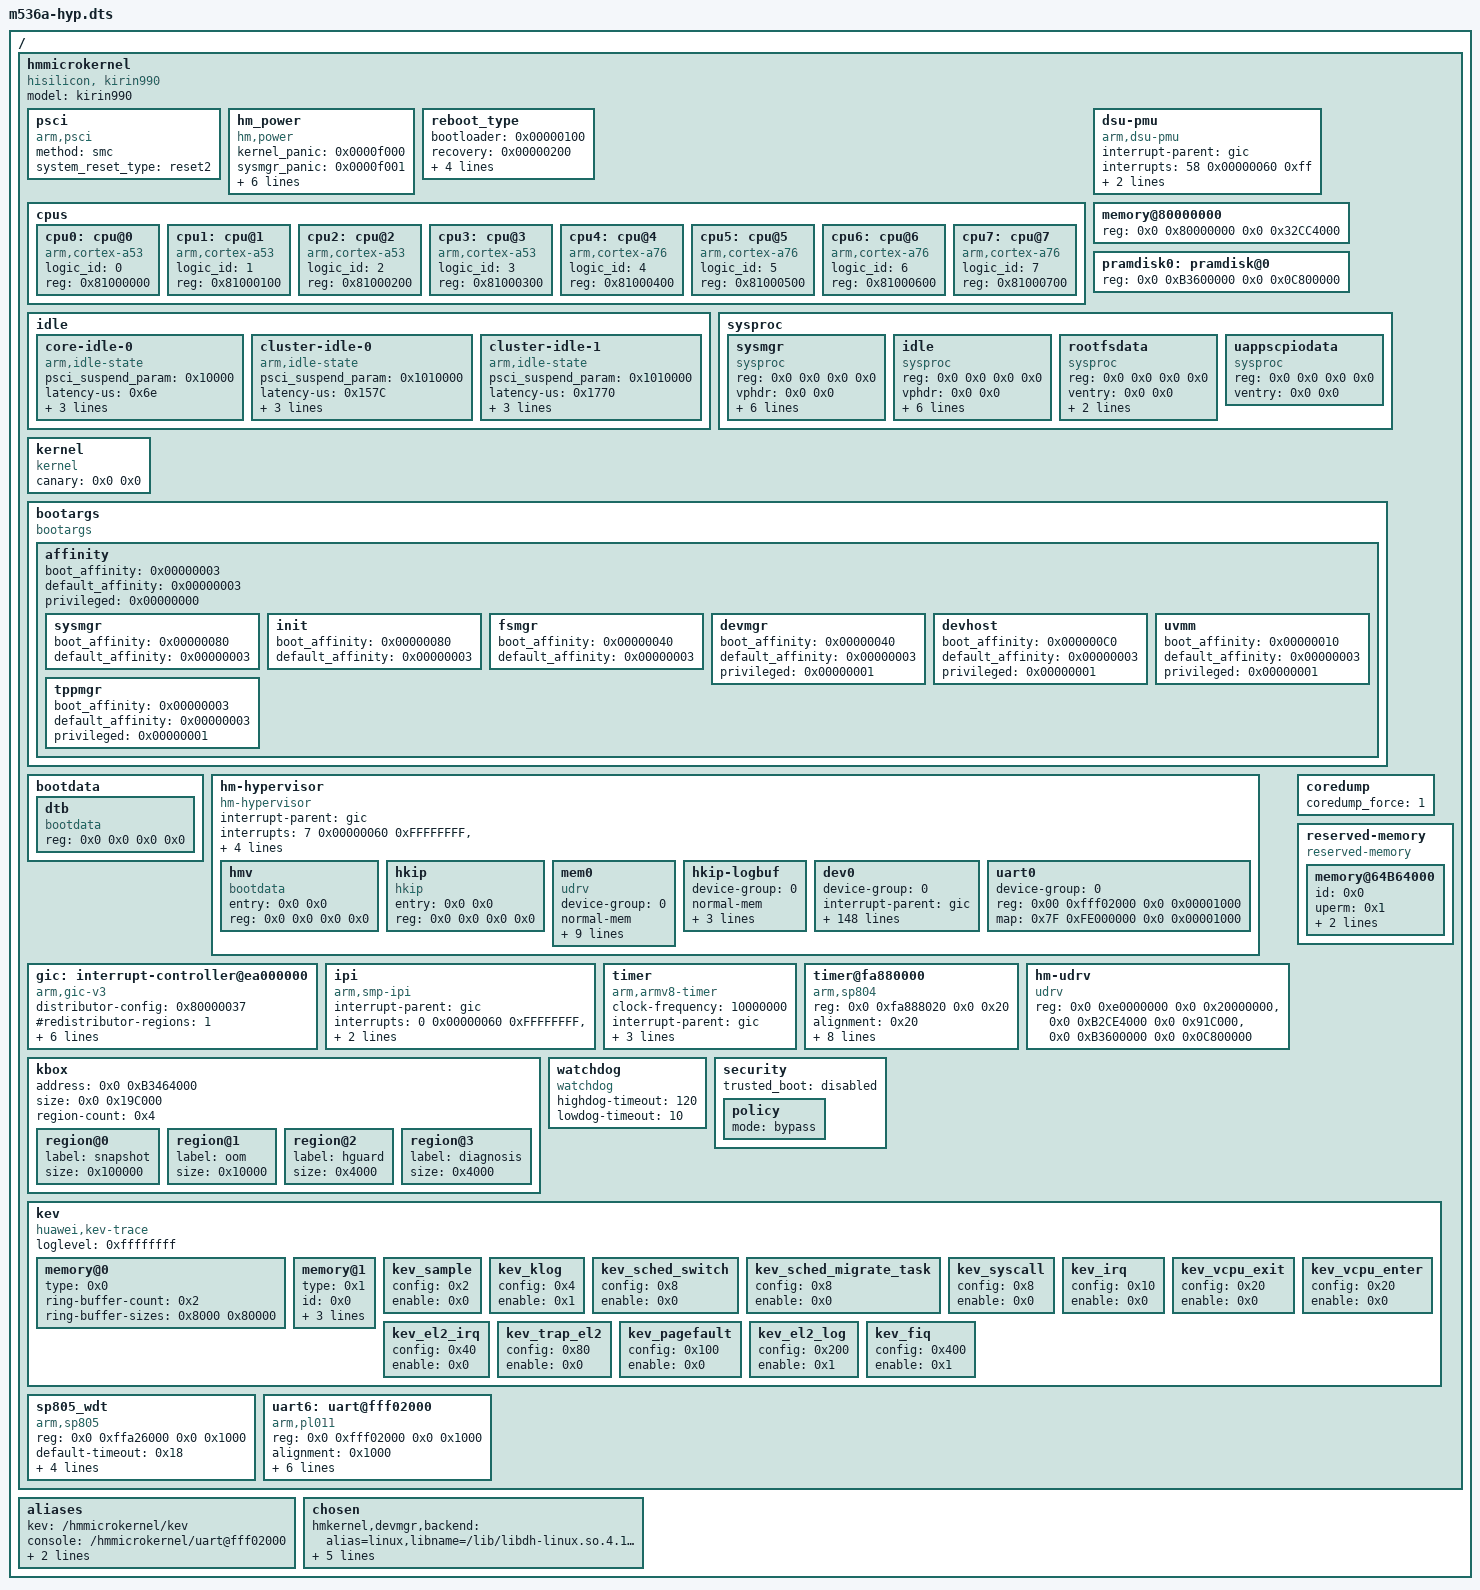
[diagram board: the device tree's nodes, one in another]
/dts-v1/;
/ { #address-cells = <2>; #size-cells = <2>; hmmicrokernel {
	model = "kirin990";
	compatible = "hisilicon, kirin990";
	#address-cells = <2>;
	#size-cells = <2>;

	psci {
		compatible = "arm,psci";
		method = "smc";
		system_reset_type = "reset2";
	};

	hm_power {
		compatible = "hm,power";
		kernel_panic = <0x0000f000>;
		sysmgr_panic = <0x0000f001>;
		init_panic = <0x0000f002>;
		harddog_hungry = <0x0000f003>;
		lowdog_hungry = <0x0000f004>;
		highdog_hungry = <0x0000f005>;
		coldboot = <0x00001000>;
		suspend_state = <0x01010000>;
	};

	reboot_type {
		bootloader = <0x00000100>;
		recovery = <0x00000200>;
		no_reason = <0x0000ff00>;
		vwatchdog = <0x0000f080>;
		fastboot = <0x00002e00>;
		hguard_service = <0x0000f081>;
	};

	cpus {
		#address-cells = <1>;
		#size-cells = <0>;
		cpu0: cpu@0 {
			compatible = "arm,cortex-a53", "arm,armv8";
			device_type = "cpu";
			logic_id = <0>;
			reg = <0x81000000>;
		};
		cpu1: cpu@1 {
			compatible = "arm,cortex-a53", "arm,armv8";
			device_type = "cpu";
			logic_id = <1>;
			reg = <0x81000100>;
		};
		cpu2: cpu@2 {
			compatible = "arm,cortex-a53", "arm,armv8";
			device_type = "cpu";
			logic_id = <2>;
			reg = <0x81000200>;
		};
		cpu3: cpu@3 {
			compatible = "arm,cortex-a53", "arm,armv8";
			device_type = "cpu";
			logic_id = <3>;
			reg = <0x81000300>;
		};
		cpu4: cpu@4 {
			compatible = "arm,cortex-a76", "arm,armv8";
			device_type = "cpu";
			logic_id = <4>;
			reg = <0x81000400>;
		};
		cpu5: cpu@5 {
			compatible = "arm,cortex-a76", "arm,armv8";
			device_type = "cpu";
			logic_id = <5>;
			reg = <0x81000500>;
		};
		cpu6: cpu@6 {
			compatible = "arm,cortex-a76", "arm,armv8";
			device_type = "cpu";
			logic_id = <6>;
			reg = <0x81000600>;
		};
		cpu7: cpu@7 {
			compatible = "arm,cortex-a76", "arm,armv8";
			device_type = "cpu";
			logic_id = <7>;
			reg = <0x81000700>;
		};
	};

	idle {
		core-idle-0 {
			compatible = "arm,idle-state";
			psci_suspend_param = <0x10000>;
			latency-us = <0x6e>;
			min-idletime-us = <0xbb8>;
			timer-stop;
			cpus = <0xff>;
		};
		cluster-idle-0 {
			compatible = "arm,idle-state";
			psci_suspend_param = <0x1010000>;
			latency-us = <0x157C>;
			min-idletime-us = <0x4e20>;
			timer-stop;
			cpus = <0xf>;
		};
		cluster-idle-1 {
			compatible = "arm,idle-state";
			psci_suspend_param = <0x1010000>;
			latency-us = <0x1770>;
			min-idletime-us = <0x3a98>;
			timer-stop;
			cpus = <0xf0>;
		};
	};

	dsu-pmu {
		compatible = "arm,dsu-pmu";
		interrupt-parent = <&gic>;
		interrupts = <58 0x00000060 0xff>;
		cpus = <&cpu0>, <&cpu1>, <&cpu2>, <&cpu3>,
			<&cpu4>, <&cpu5>, <&cpu6>, <&cpu7>;
	};

	memory@80000000 {
		device_type = "memory";
		reg = <0x0 0x80000000 0x0 0x32CC4000>;
	};

	/*
	 * used for kernel to map ramdisk memory as normal memory.
	 * memory range in this node should be exactly the same as the one in overlay-hyp.dts
	 */
	pramdisk0: pramdisk@0 {
		reg = <0x0 0xB3600000 0x0 0x0C800000>;
	};

	sysproc {
		#address-cells = <2>;
		#size-cells = <2>;
		sysmgr {
			compatible = "sysproc", "sysmgr";
			/* filled by bootloader */
			reg      = <0x0 0x0 0x0 0x0>;
			vphdr    = <0x0 0x0>;
			ventry   = <0x0 0x0>;
			pvoffset = <0x0 0x0>;
			nphdrs   = <0>;
			stack_start = <0x0 0x0>;
			stack_end = <0x0 0x0>;
			canary = <0x0 0x0>;
		};
		idle {
			compatible = "sysproc", "idle";
			/* filled by bootloader */
			reg      = <0x0 0x0 0x0 0x0>;
			vphdr    = <0x0 0x0>;
			ventry   = <0x0 0x0>;
			pvoffset = <0x0 0x0>;
			nphdrs   = <0>;
			stack_start = <0x0 0x0>;
			stack_end = <0x0 0x0>;
			canary = <0x0 0x0>;
		};
		rootfsdata {
			compatible = "sysproc", "rootfs";
			/* filled by bootloader */
			reg      = <0x0 0x0 0x0 0x0>;
			ventry   = <0x0 0x0>;
			pvoffset = <0x0 0x0>;
			jump_back = <0x0 0x0>;
		};

		uappscpiodata {
			compatible = "sysproc", "uappscpio";
			/* filled by bootloader */
			reg      = <0x0 0x0 0x0 0x0>;
			ventry   = <0x0 0x0>;
		};
	};

	kernel {
		compatible = "kernel";
		/* filled by bootloader */
		canary = <0x0 0x0>;
	};

	bootargs {
		compatible = "bootargs";
		affinity {
			boot_affinity = <0x00000003>;			/* 2 little cores */
			default_affinity = <0x00000003>;		/* 2 little cores */
			privileged = <0x00000000>;
			sysmgr {
				boot_affinity = <0x00000080>;		/* 1 big core */
				default_affinity = <0x00000003>;	/* 2 little cores */
			};
			init {
				boot_affinity = <0x00000080>;		/* 1 big core */
				default_affinity = <0x00000003>;	/* 2 little cores */
			};
			fsmgr {
				boot_affinity = <0x00000040>;		/* 1 big core */
				default_affinity = <0x00000003>;	/* 2 little cores */
			};
			devmgr {
				boot_affinity = <0x00000040>;		/* 1 big core */
				default_affinity = <0x00000003>;	/* 2 little cores */
				privileged = <0x00000001>;
			};
			devhost {
				boot_affinity = <0x000000C0>;		/* 2 big cores */
				default_affinity = <0x00000003>;	/* 2 little cores */
				privileged = <0x00000001>;
			};
			uvmm {
				boot_affinity = <0x00000010>;		/* 1 middle core */
				default_affinity = <0x00000003>;	/* 2 little cores */
				privileged = <0x00000001>;
			};
			tppmgr {
				boot_affinity = <0x00000003>;		/* 2 little cores */
				default_affinity = <0x00000003>;	/* 2 little cores */
				privileged = <0x00000001>;
			};
		};
	};

	bootdata {
		#address-cells = <2>;
		#size-cells = <2>;
		dtb {
			compatible = "bootdata", "dtb";
			/* filled by bootloader */
			reg = <0x0 0x0 0x0 0x0>;
		};
	};

	hm-hypervisor {
		compatible = "hm-hypervisor";
		#address-cells = <2>;
		#size-cells = <2>;

		interrupt-parent = <&gic>;
		interrupts = <7 0x00000060 0xFFFFFFFF>,
			     <25 0x00000060 0xFFFFFFFF>,
			     <27 0x00000060 0xFFFFFFFF>;

		virtual-timer-irq = <27>;
		vgic-base-address = <0x7F 0xFF000000>;

		hmv {
			compatible = "bootdata";
			/* filled by bootloader */
			entry = <0x0 0x0>;
			reg = <0x0 0x0 0x0 0x0>;
		};

		hkip {
			compatible = "hkip";
			/* filled by bootloader */
			entry = <0x0 0x0>;
			reg = <0x0 0x0 0x0 0x0>;
		};

		/* for vm0*/
		mem0 {
			device-group = <0>;
			compatible = "udrv";
			normal-mem;
			uvmm-access;
			reg = <0x0 0x00000000 0x0 0x80000000>,
			      <0x0 0xC0000000 0x0 0x20000000>,
			      <0x1 0x00000000 0x1 0x00000000>,
			      <0x8 0x00000000 0x0 0x20000000>;
			map = <0x0 0x00000000 0x0 0x80000000>,
			      <0x0 0xC0000000 0x0 0x20000000>,
			      <0x1 0x00000000 0x1 0x00000000>,
			      <0x8 0x00000000 0x0 0x20000000>;
		};

		hkip-logbuf {
			device-group = <0>;
			normal-mem;
			hkip-logbuf;
			reg = <0x0 0xB2CC4000 0x0 0x00020000>;
			map = <0x0 0xB2CC4000 0x0 0x00020000>;
		};

		dev0 {
			device-group = <0>;
			interrupt-parent = <&gic>;
			interrupts = <80 0x000000E0 0xFFFFFFFF>, /* timer */
				     <113 0x000000E0 0xFFFFFFFF>, /* i2c */
				     <114 0x000000E0 0xFFFFFFFF>, /* i2c */
				     <257 0x000000E0 0xFFFFFFFF>, /* i2c */
				     <346 0x000000E0 0xFFFFFFFF>, /* i2c */
				     <344 0x000000E0 0xFFFFFFFF>, /* pl022 */
				     <304 0x000000E0 0xFFFFFFFF>, /* isp */
				     <475 0x000000E0 0xFFFFFFFF>, /* HISP_CPE_IRQ */
				     <310 0x000000E0 0xFFFFFFFF>, /* ufs */
				     <169 0x000000E0 0xFFFFFFFF>, /* ufs-timer */
				     <224 0x000000E0 0xFFFFFFFF>, /* mailbox */
				     <225 0x000000E0 0xFFFFFFFF>, /* mailbox */
				     <229 0x000000E0 0xFFFFFFFF>, /* mailbox */
				     <230 0x000000E0 0xFFFFFFFF>, /* mailbox */
				     <231 0x000000E0 0xFFFFFFFF>, /* mailbox */
				     <232 0x000000E0 0xFFFFFFFF>, /* mailbox */
				     <233 0x000000E0 0xFFFFFFFF>, /* mailbox */
				     <234 0x000000E0 0xFFFFFFFF>, /* mailbox */
				     <235 0x000000E0 0xFFFFFFFF>, /* mailbox */
				     <237 0x000000E0 0xFFFFFFFF>, /* mailbox */
				     <238 0x000000E0 0xFFFFFFFF>, /* mailbox */
				     <205 0x000000E0 0xFFFFFFFF>, /* mailbox */
				     <204 0x000000E0 0xFFFFFFFF>, /* mailbox */
				     <470 0x020000E0 0xFFFFFFFF>, /* cmd-intr */
				     <472 0x020000E0 0xFFFFFFFF>, /* dfx-intr */
				     <32 0x000000E0 0xFFFFFFFF>, /* errirq */
				     <41 0x000000E0 0xFFFFFFFF>, /* faultirq */
				     <52 0x000000E0 0xFFFFFFFF>, /* pmu */
				     <53 0x000000E0 0xFFFFFFFF>, /* pmu */
				     <54 0x000000E0 0xFFFFFFFF>, /* pmu */
				     <55 0x000000E0 0xFFFFFFFF>, /* pmu */
				     <56 0x000000E0 0xFFFFFFFF>, /* pmu */
				     <57 0x000000E0 0xFFFFFFFF>, /* pmu */
				     <315 0x000000E0 0xFFFFFFFF>, /* kirin-pcie0-msi */
				     <316 0x020000E0 0xFFFFFFFF>, /* kirin-pcie0-intc */
				     <317 0x020000E0 0xFFFFFFFF>, /* kirin-pcie0-intd */
				     <313 0x020000E0 0xFFFFFFFF>, /* kirin-pcie0-linkdown */
				     <243 0x020000E0 0xFFFFFFFF>, /* kirin-pcie0-cpltimeout */
				     <449 0x000000E0 0xFFFFFFFF>, /* kirin-pcie1-msi */
				     <450 0x020000E0 0xFFFFFFFF>, /* kirin-pcie1-intc */
				     <451 0x020000E0 0xFFFFFFFF>, /* kirin-pcie1-intd */
				     <415 0x020000E0 0xFFFFFFFF>, /* kirin-pcie1-linkdown */
				     <244 0x020000E0 0xFFFFFFFF>, /* kirin-pcie1-cpltimeout */
				     <290 0x000000E0 0xFFFFFFFF>, /* gpu */
				     <291 0x000000E0 0xFFFFFFFF>, /* gpu */
				     <292 0x000000E0 0xFFFFFFFF>, /* gpu */
				     <277 0x000000E0 0xFFFFFFFF>, /* irq_pdp */
				     <278 0x000000E0 0xFFFFFFFF>, /* irq_pdp */
				     <279 0x000000E0 0xFFFFFFFF>, /* irq_adp */
				     <283 0x000000E0 0xFFFFFFFF>, /* irq_dsi0 */
				     <284 0x000000E0 0xFFFFFFFF>, /* irq_dsi0 */
				     <363 0x000000E0 0xFFFFFFFF>, /* dwc_dptx */
				     <319 0x000000E0 0xFFFFFFFF>, /* irq_mdc */
				     <388 0x000000E0 0xFFFFFFFF>, /* irq_sdp */
				     <335 0x000000E0 0xFFFFFFFF>, /* irq_jpu_dec_merged */
				     <175 0x000000E0 0xFFFFFFFF>, /* hisi-dma64 */
				     <376 0x000000E0 0xFFFFFFFF>, /* tc_ns_client */
				     <465 0x000000E0 0xFFFFFFFF>, /* npu-mailbox-0 */
				     <467 0x000000E0 0xFFFFFFFF>, /* npu-mailbox-4 */
				     <468 0x000000E0 0xFFFFFFFF>, /* npu-mailbox-5 */
				     <569 0x000000E0 0xFFFFFFFF>, /* hisi-mmu-v8-gerror */
				     <248 0x000000E0 0xFFFFFFFF>, /* asp_dma_irq */
				     <245 0x000000E0 0xFFFFFFFF>, /* soc wdt handler */
				     <191 0x000000E0 0xFFFFFFFF>, /* dwc3 */
				     <78 0x000000E0 0xFFFFFFFF>, /* hisi-soc-rtc */
				     <116 0x000000E0 0xFFFFFFFF>, /* gpio interrupt */
				     <117 0x000000E0 0xFFFFFFFF>, /* gpio interrupt */
				     <118 0x000000E0 0xFFFFFFFF>, /* gpio interrupt */
				     <119 0x000000E0 0xFFFFFFFF>, /* gpio interrupt */
				     <120 0x000000E0 0xFFFFFFFF>, /* gpio interrupt */
				     <121 0x000000E0 0xFFFFFFFF>, /* gpio interrupt */
				     <122 0x000000E0 0xFFFFFFFF>, /* gpio interrupt */
				     <123 0x000000E0 0xFFFFFFFF>, /* gpio interrupt */
				     <124 0x000000E0 0xFFFFFFFF>, /* gpio interrupt */
				     <125 0x000000E0 0xFFFFFFFF>, /* gpio interrupt */
				     <126 0x000000E0 0xFFFFFFFF>, /* gpio interrupt */
				     <127 0x000000E0 0xFFFFFFFF>, /* gpio interrupt */
				     <128 0x000000E0 0xFFFFFFFF>, /* gpio interrupt */
				     <129 0x000000E0 0xFFFFFFFF>, /* gpio interrupt */
				     <130 0x000000E0 0xFFFFFFFF>, /* gpio interrupt */
				     <131 0x000000E0 0xFFFFFFFF>, /* gpio interrupt */
				     <132 0x000000E0 0xFFFFFFFF>, /* gpio interrupt */
				     <133 0x000000E0 0xFFFFFFFF>, /* gpio interrupt */
				     <134 0x000000E0 0xFFFFFFFF>, /* gpio interrupt */
				     <135 0x000000E0 0xFFFFFFFF>, /* gpio interrupt */
				     <136 0x000000E0 0xFFFFFFFF>, /* gpio interrupt */
				     <137 0x000000E0 0xFFFFFFFF>, /* gpio interrupt */
				     <138 0x000000E0 0xFFFFFFFF>, /* gpio interrupt */
				     <139 0x000000E0 0xFFFFFFFF>, /* gpio interrupt */
				     <140 0x000000E0 0xFFFFFFFF>, /* gpio interrupt */
				     <141 0x000000E0 0xFFFFFFFF>, /* gpio interrupt */
				     <142 0x000000E0 0xFFFFFFFF>, /* gpio interrupt */
				     <143 0x000000E0 0xFFFFFFFF>, /* gpio interrupt */
				     <144 0x000000E0 0xFFFFFFFF>, /* gpio interrupt */
				     <145 0x000000E0 0xFFFFFFFF>, /* gpio interrupt */
				     <146 0x000000E0 0xFFFFFFFF>, /* gpio interrupt */
				     <147 0x000000E0 0xFFFFFFFF>, /* gpio interrupt */
				     <148 0x000000E0 0xFFFFFFFF>, /* gpio interrupt */
				     <149 0x000000E0 0xFFFFFFFF>, /* gpio interrupt */
				     <150 0x000000E0 0xFFFFFFFF>, /* gpio interrupt */
				     <151 0x000000E0 0xFFFFFFFF>, /* gpio interrupt */
				     <152 0x000000E0 0xFFFFFFFF>, /* gpio interrupt */
				     <168 0x000000E0 0xFFFFFFFF>, /* asp irq */
				     <409 0x000000E0 0xFFFFFFFF>, /* hisilicon,designware-i2c */
				     <410 0x000000E0 0xFFFFFFFF>, /* hisilicon,designware-i2c */
				     <404 0x000000E0 0xFFFFFFFF>, /* spi */
				     <112 0x000000E0 0xFFFFFFFF>, /* spi */
				     <167 0x000000E0 0xFFFFFFFF>, /* dx,cc63p */
				     <81 0x000000E0 0xFFFFFFFF>, /* timer */
				     <336 0x000000E0 0xFFFFFFFF>, /* hisp-hfd */
				     <176 0x000000E0 0xFFFFFFFF>, /* pimon_mntn */
				     <334 0x000000E0 0xFFFFFFFF>, /* hjpeg */
				     <91 0x000000E0 0xFFFFFFFF>, /* ddrc-flux */
				     <314 0x000000E0 0xFFFFFFFF>, /* kirin-pcie */
				     <286 0x000000E0 0xFFFFFFFF>, /* smmu */
				     <287 0x000000E0 0xFFFFFFFF>, /* hisi-ivp */
				     <307 0x000000E0 0xFFFFFFFF>, /* hisi-ivp */
				     <95 0x020000E0 0xFFFFFFFF>, /* timekeeper */
				     <350 0x000000E0 0xFFFFFFFF>, /* dmsspt */
				     <322 0x000000E0 0xFFFFFFFF>, /* HiVCodecV500-vdec */
				     <323 0x000000E0 0xFFFFFFFF>, /* HiVCodecV500-vdec */
				     <324 0x000000E0 0xFFFFFFFF>, /* HiVCodecV500-vdec */
				     <85 0x000000E0 0xFFFFFFFF>, /* timer */
				     <86 0x000000E0 0xFFFFFFFF>, /* timer */
				     <87 0x000000E0 0xFFFFFFFF>, /* timer */
				     <88 0x000000E0 0xFFFFFFFF>, /* timer */
				     <92 0x000000E0 0xFFFFFFFF>, /* timer */
				     <96 0x000000E0 0xFFFFFFFF>, /* timer */
				     <97 0x000000E0 0xFFFFFFFF>, /* timer */
				     <105 0x000000E0 0xFFFFFFFF>, /* timer */
				     <343 0x000000E0 0xFFFFFFFF>, /* balong */
				     <68 0x000000E0 0xFFFFFFFF>, /* int */
				     <70 0x000000E0 0xFFFFFFFF>, /* int */
				     <72 0x000000E0 0xFFFFFFFF>, /* int */
				     <74 0x000000E0 0xFFFFFFFF>, /* int */
				     <73 0x000000E0 0xFFFFFFFF>, /* int */
				     <75 0x000000E0 0xFFFFFFFF>, /* int */
				     <174 0x000000E0 0xFFFFFFFF>, /* int42 */
				     <49 0x000000E0 0xFFFFFFFF>, /* int46 */
				     <71 0x000000E0 0xFFFFFFFF>, /* int17 */
				     <69 0x000000E0 0xFFFFFFFF>, /* int16 */
				     <165 0x000000E0 0xFFFFFFFF>, /* int25 */
				     <530 0x000000E0 0xFFFFFFFF>, /* sim_sock_srv */
				     <159 0x000000E0 0xFFFFFFFF>, /* perf */
				     <339 0x000000E0 0xFFFFFFFF>, /* hisi-fd */
				     <106 0x000000E0 0xFFFFFFFF>; /* uart-pl011 */
			reg = <0x0 0xe0000000 0x0 0x20000000>;
			map = <0x0 0xe0000000 0x0 0x20000000>;
		};

		uart0 {
			device-group = <0>;
			reg = <0x00 0xfff02000 0x0 0x00001000>;
			map = <0x7F 0xFE000000 0x0 0x00001000>;
		};
	};
	/* See Documentation/dts-gic.md for interrupts and distributor_config */
	gic: interrupt-controller@ea000000 {
		compatible = "arm,gic-v3";

		#address-cells = <2>;
		#size-cells = <2>;
		distributor-config = <0x80000037>;
		#interrupt-cells = <3>;
		#redistributor-regions = <1>;
		redistributor-stride = <0x20000>;
		interrupt-controller;
		/* the value must be positive */
		irqctrl_id = <0x10000>;

		reg =	<0x0 0xFE400000 0x0 0x10000>,   /* GICD */
			<0x0 0xFE440000 0x0 0x100000>;  /* GICR */
		alignment = <0x10000 0x10000>;
	};

	ipi {
		/* smp ipi */
		compatible = "arm,smp-ipi";

		interrupt-parent = <&gic>;

		/* interrupt settings:
		 * 1st cell: real hardware irq number
		 *     ARM recommendation: ID 0-7 for Non-Secure;
		 *                         ID 8-15 for Secure Interrupt
		 * 2nd cell: interrupt config
		 *     bit [27:26]: Group setting
		 *     bit [24]: Trigger Type
		 *     bit [23:8]: Reserved
		 *     bit [7:0]: Priority
		 * 3rd cell: interrupt target config
		 *     Warning: Send all cpus by defult
		 */
		interrupts =	<0 0x00000060 0xFFFFFFFF>, /* IPI_RESCHEDULE */
				<1 0x00000060 0xFFFFFFFF>, /* IPI_CALL_FUNC */
				<2 0x00000060 0xFFFFFFFF>; /* IPI_CPU_STOP */
	};

	timer {
		compatible = "arm,armv8-timer";
		clock-frequency = <10000000>;

		/* interrupt settings */
		interrupt-parent = <&gic>;

		/* PPI 30: Non-secure physical timer
		 * level triggered, hwprio:2 */
		interrupts = <30 0x00000060 0xFFFFFFFF>,
			     <26 0x00000060 0xFFFFFFFF>;
		tock_start = <0 0>;
	};

	timer@fa880000 {
		compatible = "arm,sp804", "arm,primecell";
		reg = <0x0 0xfa888020 0x0 0x20>;
		alignment = <0x20>;
		clock-frequency = <32764>;
		clockevent-frequency = <32764>;
		clocks = <0xff 0xff 0x1d>;
		clock-names = "osc32khz", "osc32khz", "apb_pclk";
		/* this timer should be driven by kernel */
		kernel-tick;
		status = "ok";
		phandle = <0x563>;
		prescale = <1>;
		value = <0xffffffff>;
		interrupt-parent = <&gic>;
		interrupts = <97 0x00000060 0xFFFFFFFF>;
	};

	hm-udrv {
		compatible = "udrv";
		reg = <0x0 0xe0000000 0x0 0x20000000>,
		      <0x0 0xB2CE4000 0x0 0x91C000>, /* kev and kbox */
		      <0x0 0xB3600000 0x0 0x0C800000>;
	};

	kbox {
			address = <0x0 0xB3464000>;
			size = <0x0 0x19C000>;
			region-count= <0x4>;
			region@0 {
				label = "snapshot";
				size = <0x100000>;
			};
			region@1 {
				label = "oom";
				size = <0x10000>;
			};
			region@2 {
				label = "hguard";
				size = <0x4000>;
			};
			region@3 {
				label = "diagnosis";
				size = <0x4000>;
			};
		};

	watchdog {
		compatible = "watchdog";
		/* reserve 120s for hguard to take over the watchdog */
		highdog-timeout= <120>;
		/* reserve 10s for subcore to pull up*/
		lowdog-timeout = <10>;
	};

	coredump {
		coredump_force = <1>;
	};
	security {
		trusted_boot = "disabled";
		policy {
			mode = "bypass";
		};
	};

	/*
	 * The prop uperm means the user permission of the memory
	 * The uperm attribute is not configured means it has UPERM_ALL
	 * The uperm attribute is set to 0x0 means this range is not accessible in user mode
	 * The uperm attribute is set to 0x1 means this range only readable in user mode
	 */
	reserved-memory {
		compatible = "reserved-memory";
		#address-cells = <2>;
		#size-cells = <2>;
		memory@64B64000 {
			id = <0x0>;
			uperm = <0x1>;
			reg = <0x0 0xB2CE4000 0x0 0x780000>;
			alignment = <0x1000>;
		};
	};
	kev {
		compatible = "huawei,kev-trace";

		loglevel = <0xffffffff>; /* will be updated from boot cmdline */
		memory@0 {
			type = <0x0>;
			ring-buffer-count = <0x2>;
			/*
			 * ring buffer 0: 32K (the default memory used by trace items not defined in dts)
			 * ring buffer 1: 512K (sample)
			 */
			ring-buffer-sizes = <0x8000 0x80000>;
		};
		memory@1 {
			type = <0x1>; /* reserved memory */
			id = <0x0>;
			ring-buffer-count = <0x9>;
			/*
			 * Only ring buffer DATA sizes. Memory head and ring
			 * buffer heads are not included.
			 * ring buffer 2: 4MB(klog)
			 * ring buffer 3: 1MB(sched, syscall)
			 * ring buffer 4: 512KB(irq)
			 * ring buffer 5: 512KB(vcpu_exit/vcpu_enter)
			 * ring buffer 6: 512KB(el2_irq)
			 * ring buffer 7: 256KB(trap_el2)
			 * ring buffer 8: 128KB(pagefault)
			 * ring buffer 9: 128KB(el2_log)
			 * ring buffer 10: 8KB(fiq)
			 */
			ring-buffer-sizes = <0x400000 0x100000 0x80000 0x80000 0x80000 0x40000 0x20000 0x20000 0x2000>;
		};
		kev_sample {
			config = <0x2>;
			enable = <0x0>;
		};
		kev_klog {
			config = <0x4>;
			enable = <0x1>;
		};
		kev_sched_switch {
			config = <0x8>;
			enable = <0x0>;
		};
		kev_sched_migrate_task {
			config = <0x8>;
			enable = <0x0>;
		};
		kev_syscall {
			config = <0x8>;
			enable = <0x0>;
		};
		kev_irq {
			config = <0x10>;
			enable = <0x0>;
		};
		kev_vcpu_exit {
			config = <0x20>;
			enable = <0x0>;
		};
		kev_vcpu_enter {
			config = <0x20>;
			enable = <0x0>;
		};
		kev_el2_irq {
			config = <0x40>;
			enable = <0x0>;
		};
		kev_trap_el2 {
			config = <0x80>;
			enable = <0x0>;
		};
		kev_pagefault {
			config = <0x100>;
			enable = <0x0>;
		};
		kev_el2_log {
			config = <0x200>;
			enable = <0x1>;
		};
		kev_fiq {
			config = <0x400>;
			enable = <0x1>;
		};
	};

	sp805_wdt {
		compatible = "arm,sp805", "arm,primecell";
		reg = <0x0 0xffa26000 0x0 0x1000>;
		default-timeout = <0x18>;
		interrupt-parent = <&gic>;
		/* The frequency of sp805 WDOGCLK on m536a is 32764 Hz. */
		clock-frequency = <0x0 0x00007FFC>;
		status = "ok";
		alignment = <0x20000>;
		enabled = <1>;
	};

	uart6: uart@fff02000 {
		compatible = "arm,pl011", "arm,pl011,uart";
		reg = <0x0 0xfff02000 0x0 0x1000>;
		alignment = <0x1000>;

		kernel-input;
		fifo-enabled;
		/*
		 * kernel-disable equals to 0 means kernel is not disable,
		 * 1 means disable serial but allow dynamic toggle,
		 * 2 means disable serial and disallow toggle.
		 */
		kernel-disable = <0>;

		interrupt-parent = <&gic>;
		/* secure irq, group setting is 0b11 bit[27:26] */
		interrupts = <111 0x00000060 0x00000001>; /* pl011 uart6 interrupt for receiving */
		loglevel = <0xffffffff>; /* will be updated from boot cmdline */
	};
	}; /* end of hmmicrokernel */

	aliases {
		/* aliases for aliasarg nodes */
		kev = "/hmmicrokernel/kev";
		console = "/hmmicrokernel/uart@fff02000";
		watchdog = "/hmmicrokernel/sp805_wdt";
		timer = "/hmmicrokernel/timer";
	};

	chosen {
		/* config devhost backend */
		hmkernel,devmgr,backend =
			"alias=linux,libname=/lib/libdh-linux.so.4.14-m536a,modpath=/lib/modules,default";

		/* config root devhost */
		hmkernel,devmgr,root,backend = "linux";
		hmkernel,devmgr,root,extensions = "lib/extension/libdhext_dfx.so";
		hmkernel,devmgr,root,args = "reboot_reason=no_reason";
	};

};
